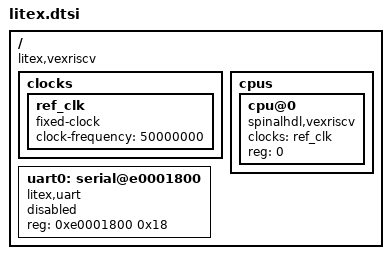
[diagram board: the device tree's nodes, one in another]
// SPDX-License-Identifier: GPL-2.0-only

/dts-v1/;

/ {
	compatible = "litex,vexriscv", "litex-dev";

	#address-cells = <1>;
	#size-cells = <1>;

	clocks {
		ref_clk: ref_clk {
			#clock-cells = <0>;
			compatible = "fixed-clock";
			clock-frequency = <50000000>;
		};
	};

	cpus {
		#address-cells = <1>;
		#size-cells = <0>;

		cpu@0 {
			device_type = "cpu";
			compatible = "spinalhdl,vexriscv", "riscv";
			clocks = <&ref_clk>;
			reg = <0>;
		};
	};

	uart0: serial@e0001800 {
		compatible = "litex,uart";
		reg = <0xe0001800 0x18>;
		status = "disabled";
	};
};
